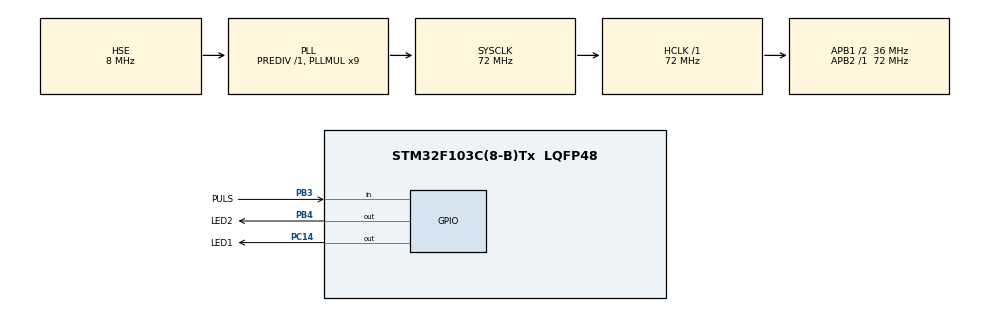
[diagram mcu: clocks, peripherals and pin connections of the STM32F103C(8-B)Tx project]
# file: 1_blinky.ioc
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Mcu.Family=STM32F1
Mcu.Name=STM32F103C(8-B)Tx
Mcu.Package=LQFP48
NVIC.PriorityGroup=NVIC_PRIORITYGROUP_4
NVIC.TIM1_UP_IRQn=true\:0\:0\:false\:false\:true\:false\:true
NVIC.TimeBase=TIM1_UP_IRQn
NVIC.TimeBaseIP=TIM1
PA13.Mode=Serial_Wire
PA13.Signal=SYS_JTMS-SWDIO
PA14.Mode=Serial_Wire
PA14.Signal=SYS_JTCK-SWCLK
PB3.GPIO_Label=PULS
PB3.Signal=GPIO_Input
PB4.GPIO_Label=LED2
PB4.Signal=GPIO_Output
PC14-OSC32_IN.GPIO_Label=LED1
PC14-OSC32_IN.Signal=GPIO_Output
PD0-OSC_IN.Mode=HSE-External-Oscillator
PD0-OSC_IN.Signal=RCC_OSC_IN
PD1-OSC_OUT.Mode=HSE-External-Oscillator
PD1-OSC_OUT.Signal=RCC_OSC_OUT
ProjectManager.HeapSize=0x200
ProjectManager.StackSize=0x400
ProjectManager.TargetToolchain=STM32CubeIDE
RCC.AHBFreq_Value=72000000
RCC.APB1CLKDivider=RCC_HCLK_DIV2
RCC.APB1Freq_Value=36000000
RCC.APB1TimFreq_Value=72000000
RCC.APB2Freq_Value=72000000
RCC.APB2TimFreq_Value=72000000
RCC.HCLKFreq_Value=72000000
RCC.PLLMUL=RCC_PLL_MUL9
RCC.PLLSourceVirtual=RCC_PLLSOURCE_HSE
RCC.SYSCLKFreq_VALUE=72000000
RCC.SYSCLKSource=RCC_SYSCLKSOURCE_PLLCLK
RCC.USBFreq_Value=72000000
VP_SYS_VS_tim1.Mode=TIM1
board=custom

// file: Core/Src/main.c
/* USER CODE BEGIN Header */
/**
  ******************************************************************************
  * @file           : main.c
  * @brief          : Main program body
  ******************************************************************************
  * @attention
  *
  * <h2><center>&copy; Copyright (c) 2023 STMicroelectronics.
  * All rights reserved.</center></h2>
  *
  * This software component is licensed by ST under BSD 3-Clause license,
  * the "License"; You may not use this file except in compliance with the
  * License. You may obtain a copy of the License at:
  *                        opensource.org/licenses/BSD-3-Clause
  *
  ******************************************************************************
  */
/* USER CODE END Header */
#include "main.h"

/* USER CODE BEGIN Includes */
#include "FreeRTOS.h"
#include "task.h"
/* USER CODE END Includes */

/* USER CODE BEGIN PV */
TaskHandle_t led_ON_Handle;
TaskHandle_t led_OFF_Handle;
/* USER CODE END PV */

void SystemClock_Config(void);
static void MX_GPIO_Init(void);

/* USER CODE BEGIN 0 */

static void led_ON( void *pvParameters) {

	while (1){
		if (HAL_GPIO_ReadPin(PULS_GPIO_Port, PULS_Pin)){
			HAL_GPIO_WritePin(LED2_GPIO_Port, LED2_Pin, GPIO_PIN_SET);
		}

		vTaskDelay(400 / portTICK_PERIOD_MS);
		vTaskResume( led_OFF_Handle );
		vTaskSuspend( led_ON_Handle );

	}

}

static void led_OFF( void *pvParameters) {

	while (1){
		if (HAL_GPIO_ReadPin(PULS_GPIO_Port, PULS_Pin)){
			HAL_GPIO_WritePin(LED2_GPIO_Port, LED2_Pin, GPIO_PIN_RESET);
		}

		vTaskDelay(600 / portTICK_PERIOD_MS);
		vTaskResume( led_ON_Handle );
		vTaskSuspend( led_OFF_Handle );

	}

}

// Tarea en caso de tener que usar una tarea distinta para leer el pulsador
static void read_Button( void *pvParameters) {

	while (1){
		if (HAL_GPIO_ReadPin(PULS_GPIO_Port, PULS_Pin)){
			vTaskResume( led_ON_Handle );
		}
		else{
			vTaskSuspend( led_ON_Handle );
			vTaskSuspend( led_OFF_Handle );
		}

		vTaskDelay(100 / portTICK_PERIOD_MS);

	}

}

/* USER CODE END 0 */

int main(void)
{

  /* MCU Configuration--------------------------------------------------------*/

  /* Reset of all peripherals, Initializes the Flash interface and the Systick. */
  HAL_Init();

  /* Configure the system clock */
  SystemClock_Config();

  /* Initialize all configured peripherals */
  MX_GPIO_Init();
  /* USER CODE BEGIN 2 */

  xTaskCreate(led_ON,
		  "",
		  configMINIMAL_STACK_SIZE,
		  NULL,
		  1,
		  &led_ON_Handle);

  xTaskCreate(led_OFF,
  		  "",
  		  configMINIMAL_STACK_SIZE,
  		  NULL,
  		  1,
  		  &led_OFF_Handle);

  vTaskSuspend( led_OFF_Handle );

  /* USER CODE END 2 */

  /* Infinite loop */

    /* USER CODE BEGIN 3 */
  vTaskStartScheduler();
  /* USER CODE END 3 */
}

void SystemClock_Config(void)
{
  RCC_OscInitTypeDef RCC_OscInitStruct = {0};
  RCC_ClkInitTypeDef RCC_ClkInitStruct = {0};

  /** Initializes the RCC Oscillators according to the specified parameters
  * in the RCC_OscInitTypeDef structure.
  */
  RCC_OscInitStruct.OscillatorType = RCC_OSCILLATORTYPE_HSE;
  RCC_OscInitStruct.HSEState = RCC_HSE_ON;
  RCC_OscInitStruct.HSEPredivValue = RCC_HSE_PREDIV_DIV1;
  RCC_OscInitStruct.HSIState = RCC_HSI_ON;
  RCC_OscInitStruct.PLL.PLLState = RCC_PLL_ON;
  RCC_OscInitStruct.PLL.PLLSource = RCC_PLLSOURCE_HSE;
  RCC_OscInitStruct.PLL.PLLMUL = RCC_PLL_MUL9;
  if (HAL_RCC_OscConfig(&RCC_OscInitStruct) != HAL_OK)
  {
    Error_Handler();
  }
  /** Initializes the CPU, AHB and APB buses clocks
  */
  RCC_ClkInitStruct.ClockType = RCC_CLOCKTYPE_HCLK|RCC_CLOCKTYPE_SYSCLK
                              |RCC_CLOCKTYPE_PCLK1|RCC_CLOCKTYPE_PCLK2;
  RCC_ClkInitStruct.SYSCLKSource = RCC_SYSCLKSOURCE_PLLCLK;
  RCC_ClkInitStruct.AHBCLKDivider = RCC_SYSCLK_DIV1;
  RCC_ClkInitStruct.APB1CLKDivider = RCC_HCLK_DIV2;
  RCC_ClkInitStruct.APB2CLKDivider = RCC_HCLK_DIV1;

  if (HAL_RCC_ClockConfig(&RCC_ClkInitStruct, FLASH_LATENCY_2) != HAL_OK)
  {
    Error_Handler();
  }
}

static void MX_GPIO_Init(void)
{
  GPIO_InitTypeDef GPIO_InitStruct = {0};

  /* GPIO Ports Clock Enable */
  __HAL_RCC_GPIOC_CLK_ENABLE();
  __HAL_RCC_GPIOD_CLK_ENABLE();
  __HAL_RCC_GPIOA_CLK_ENABLE();
  __HAL_RCC_GPIOB_CLK_ENABLE();

  /*Configure GPIO pin Output Level */
  HAL_GPIO_WritePin(LED1_GPIO_Port, LED1_Pin, GPIO_PIN_RESET);

  /*Configure GPIO pin Output Level */
  HAL_GPIO_WritePin(LED2_GPIO_Port, LED2_Pin, GPIO_PIN_RESET);

  /*Configure GPIO pin : LED1_Pin */
  GPIO_InitStruct.Pin = LED1_Pin;
  GPIO_InitStruct.Mode = GPIO_MODE_OUTPUT_PP;
  GPIO_InitStruct.Pull = GPIO_NOPULL;
  GPIO_InitStruct.Speed = GPIO_SPEED_FREQ_LOW;
  HAL_GPIO_Init(LED1_GPIO_Port, &GPIO_InitStruct);

  /*Configure GPIO pin : PULS_Pin */
  GPIO_InitStruct.Pin = PULS_Pin;
  GPIO_InitStruct.Mode = GPIO_MODE_INPUT;
  GPIO_InitStruct.Pull = GPIO_NOPULL;
  HAL_GPIO_Init(PULS_GPIO_Port, &GPIO_InitStruct);

  /*Configure GPIO pin : LED2_Pin */
  GPIO_InitStruct.Pin = LED2_Pin;
  GPIO_InitStruct.Mode = GPIO_MODE_OUTPUT_PP;
  GPIO_InitStruct.Pull = GPIO_NOPULL;
  GPIO_InitStruct.Speed = GPIO_SPEED_FREQ_LOW;
  HAL_GPIO_Init(LED2_GPIO_Port, &GPIO_InitStruct);

}

 /**
  * @brief  Period elapsed callback in non blocking mode
  * @note   This function is called  when TIM1 interrupt took place, inside
  * HAL_TIM_IRQHandler(). It makes a direct call to HAL_IncTick() to increment
  * a global variable "uwTick" used as application time base.
  * @param  htim : TIM handle
  * @retval None
  */
void HAL_TIM_PeriodElapsedCallback(TIM_HandleTypeDef *htim)
{
  if (htim->Instance == TIM1) {
    HAL_IncTick();
  }
}

void Error_Handler(void)
{
  __disable_irq();
  while (1)
  {
  }
}

/************************ (C) COPYRIGHT STMicroelectronics *****END OF FILE****/
